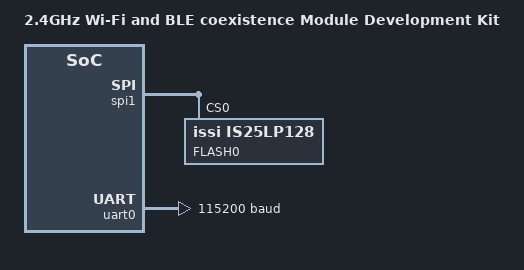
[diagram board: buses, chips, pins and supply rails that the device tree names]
/*
 * Copyright (c) 2021, ATL Electronics
 * SPDX-License-Identifier: Apache-2.0
 */

/dts-v1/;

#include "dt_bl10_devkit-pinctrl.dtsi"

/ {
	model = "2.4GHz Wi-Fi and BLE coexistence Module Development Kit";
	compatible = "bflb,bl602";

	chosen {
		zephyr,flash = &flash0;
		zephyr,itcm = &itcm;
		zephyr,dtcm = &dtcm;
		zephyr,sram = &sram0;
		zephyr,console = &uart0;
		zephyr,shell-uart = &uart0;
	};
};

&cpu0 {
	clock-frequency = <160000000>;
};

&spi1 {
	#address-cells = <1>;
	#size-cells = <0>;
	reg = <0x4000b000 0x1000 0x23000000 0xc00000>;
	flash0: flash@0 {
		compatible = "issi,is25lp128", "jedec,spi-nor";
		size = <134217728>;
		label = "FLASH0";
		jedec-id = [96 60 18];
		reg = <0>;
		// Dummy entry
		spi-max-frequency = <0>;
	};
};

&uart0 {
	status = "okay";
	current-speed = <115200>;

	pinctrl-0 = <&uart0_default>;
	pinctrl-1 = <&uart0_sleep>;
	pinctrl-names = "default", "sleep";
};
